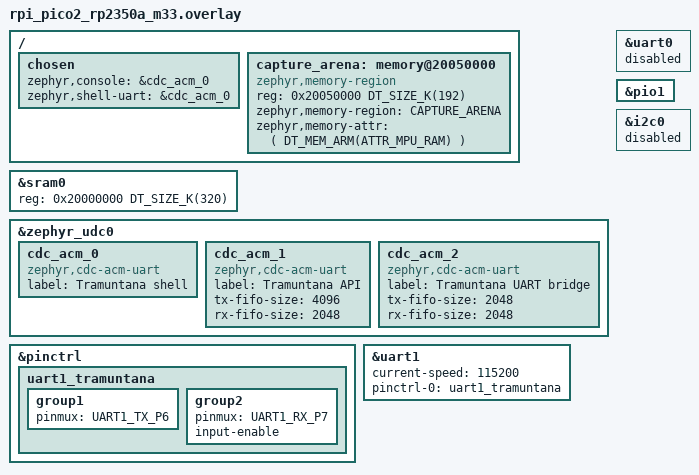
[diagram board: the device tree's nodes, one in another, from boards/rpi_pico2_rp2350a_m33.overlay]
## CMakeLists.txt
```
cmake_minimum_required(VERSION 3.20.0)

find_package(Zephyr REQUIRED HINTS $ENV{ZEPHYR_BASE})
project(tramuntana_fw)

target_sources(app PRIVATE
  src/main.c
  src/usb.c
  src/port.c
  src/board.c
  src/display.c
  src/proto.c
  src/spi.c
  src/i2c.c
  src/scope.c
  src/awg.c
  src/pwm.c
  src/logic.c
  src/bridge.c
  src/arena.c
  src/dmaring.c
  src/shell_cmds.c
  src/watch.c
  src/emu.c
  src/seq.c
  src/stamp.c
)

# images_gen.h / font_gen.h, generated by fw/imgs/convert_images.py and
# fw/imgs/font_gen.py.
target_include_directories(app PRIVATE ${CMAKE_CURRENT_SOURCE_DIR}/../../imgs)
```

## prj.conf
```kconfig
# Tramuntana Lite r1a - main firmware: a USB composite device with three
# CDC-ACM ports (shell / binary API / UART bridge) driving the board's
# instruments. See src/main.c for the map.

CONFIG_GPIO=y
CONFIG_REGULATOR=y
CONFIG_DISPLAY=y
CONFIG_SPI=y
CONFIG_ADC=y
CONFIG_PWM=y
CONFIG_DMA=y
CONFIG_SERIAL=y
CONFIG_UART_INTERRUPT_DRIVEN=y
CONFIG_UART_USE_RUNTIME_CONFIGURE=y
CONFIG_UART_LINE_CTRL=y
CONFIG_HWINFO=y
CONFIG_CRC=y

# USB device (new stack), three CDC-ACM instances registered by src/usb.c.
CONFIG_USB_DEVICE_STACK_NEXT=y
CONFIG_USBD_CDC_ACM_CLASS=y
# CDC-ACM class work (rx/tx fifo handling, irq callbacks) on its own
# thread rather than the system workqueue, so USB never competes with
# the display/LED work items and vice versa.
CONFIG_USBD_CDC_ACM_WORKQUEUE=y
CONFIG_USBD_CDC_ACM_STACK_SIZE=2048
# The shell (and its log backend) runs over CDC-ACM, so the class can't
# log itself without recursing: Zephyr would force this anyway.
CONFIG_USBD_CDC_ACM_LOG_LEVEL_OFF=y

# Shell on the first CDC-ACM port (chosen zephyr,shell-uart in the overlay).
CONFIG_SHELL=y
CONFIG_SHELL_BACKEND_SERIAL=y
CONFIG_SHELL_PROMPT_UART="tramuntana:~$ "
CONFIG_SHELL_CMD_BUFF_SIZE=512
CONFIG_SHELL_ARGC_MAX=40
CONFIG_SHELL_STACK_SIZE=4096
CONFIG_LOG=y
CONFIG_LOG_MODE_DEFERRED=y
CONFIG_LOG_BUFFER_SIZE=2048

CONFIG_MAIN_STACK_SIZE=4096
CONFIG_SYSTEM_WORKQUEUE_STACK_SIZE=2048
CONFIG_HEAP_MEM_POOL_SIZE=8192
CONFIG_CBPRINTF_FP_SUPPORT=y
CONFIG_FPU=y

# The instruments drive the ADC, PWM, DMA and PIO blocks straight
# through the Pico SDK (hardware/*.h); the Zephyr drivers above are what
# pull those SDK sources in (PICOSDK_USE_* are selected by them) and
# bring the blocks out of reset at boot.
```

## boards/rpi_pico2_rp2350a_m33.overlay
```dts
/*
 * Tramuntana Lite r1a on a Pico 2 - see fw/boards/tramuntana_lite_r1a-
 * common.dtsi for the hardware itself. This overlay adds what this app
 * needs on top:
 *
 *   - three CDC-ACM ports on the Pico's USB: cdc_acm_0 (shell/console),
 *     cdc_acm_1 (binary API, src/proto.c), cdc_acm_2 (UART bridge to
 *     &uart1 on DIO1/DIO0, src/bridge.c);
 *   - &uart1 enabled on GPIO6/GPIO7 (its pins are handed over to it only
 *     while the bridge is open, see src/board.c), &uart0 disabled;
 *   - a 192KB "capture arena" carved out of the top of SRAM at a fixed,
 *     128KB-aligned address, so the DMA ring buffers (scope, logic
 *     analyzer, sniffers) can use the DMA's address-wrapping mode without
 *     the linker having to pad .bss to reach an aligned address.
 */

#include "../../../boards/tramuntana_lite_r1a-common.dtsi"
#include <zephyr/dt-bindings/memory-attr/memory-attr-arm.h>

/ {
  chosen {
    zephyr,console = &cdc_acm_0;
    zephyr,shell-uart = &cdc_acm_0;
  };

  capture_arena: memory@20050000 {
    compatible = "zephyr,memory-region", "mmio-sram";
    reg = <0x20050000 DT_SIZE_K(192)>;
    zephyr,memory-region = "CAPTURE_ARENA";
    zephyr,memory-attr = <( DT_MEM_ARM(ATTR_MPU_RAM) )>;
  };
};

/* 520KB total; the arena above takes the top 192KB, the 8KB of scratch
 * banks past 0x20080000 are left alone. */
&sram0 {
  reg = <0x20000000 DT_SIZE_K(320)>;
};

&zephyr_udc0 {
  cdc_acm_0: cdc_acm_0 {
    compatible = "zephyr,cdc-acm-uart";
    label = "Tramuntana shell";
  };
  cdc_acm_1: cdc_acm_1 {
    compatible = "zephyr,cdc-acm-uart";
    label = "Tramuntana API";
    tx-fifo-size = <4096>;
    rx-fifo-size = <2048>;
  };
  cdc_acm_2: cdc_acm_2 {
    compatible = "zephyr,cdc-acm-uart";
    label = "Tramuntana UART bridge";
    tx-fifo-size = <2048>;
    rx-fifo-size = <2048>;
  };
};

/* UART1 = GPIO6 (TX, DIO1) / GPIO7 (RX, DIO0). On the RP2350 these are
 * UART1's CTS/RTS pins, which carry TX/RX through the UART_AUX function
 * (F11), so the bridge gets pins of its own instead of sharing DIO6/DIO7
 * with I2C. src/board.c re-muxes them as the bridge opens and closes. */
&pinctrl {
  uart1_tramuntana: uart1_tramuntana {
    group1 {
      pinmux = <UART1_TX_P6>;
    };

    group2 {
      pinmux = <UART1_RX_P7>;
      input-enable;
    };
  };
};

&uart1 {
  status = "okay";
  current-speed = <115200>;
  pinctrl-0 = <&uart1_tramuntana>;
  pinctrl-names = "default";
};

/* The stock console UART (GPIO0/GPIO1 = DIO7/DIO6) is not used: the
 * console is cdc_acm_0 and those pins belong to I2C. */
&uart0 {
  status = "disabled";
};

/* PIO1 hosts the emulated I2C/SPI targets (src/emu.c); PIO0 is the
 * sniffers' and the logic analyzer's. */
&pio1 {
  status = "okay";
};

/* The hardware I2C0 block is not used (the I2C master is bit-banged so
 * arbitrary START/STOP sequences can be scripted, see src/i2c.c). */
&i2c0 {
  status = "disabled";
};
```

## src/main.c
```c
/*
 * Tramuntana Lite r1a - main firmware.
 *
 * A bench tool for poking at embedded systems: SPI and I2C master and
 * sniffer, oscilloscope, waveform generator, 8-channel logic analyzer
 * and a USB-UART bridge, all on the RP2350 of a Pico 2 running Zephyr.
 *
 * Structure (src/):
 *
 *   usb.c       USB composite device: three CDC-ACM ports
 *   port.c      irq-driven ring-buffered serial port helper
 *   proto.c/h   binary API on the second port (the protocol reference)
 *   shell_cmds.c  human shell on the first port
 *   bridge.c    USB <-> UART1 bridge on the third port
 *   board.c     LED, target power, pull-ups, DIO GPIO, pin arbiter
 *   display.c   ST7735R dashboard
 *   arena.c     capture memory (DMA ring buffers)
 *   spi.c  i2c.c  scope.c  awg.c  logic.c  pwm.c   the instruments
 *   emu.c       the board as an I2C/SPI target (register file on PIO1)
 *   seq.c       sequencer: host-uploaded steps run with us timing
 *   watch.c     timestamped DIO edges for the host's timeline
 *
 * Host side: host/python (library + CLI) and host/webapp (Web Serial).
 */

#include <zephyr/kernel.h>
#include <zephyr/logging/log.h>

#include "usb.h"
#include "board.h"
#include "display.h"
#include "proto.h"
#include "spi.h"
#include "i2c.h"
#include "scope.h"
#include "awg.h"
#include "logic.h"
#include "bridge.h"
#include "watch.h"
#include "emu.h"
#include "seq.h"
#include "stamp.h"
#include "version.h"

LOG_MODULE_REGISTER(main, LOG_LEVEL_INF);

#define SPLASH_MS 1500

int main(void)
{
  usb_init();
  board_init();
  display_init();
  stamp_init();

  spi_drv_init();
  i2c_drv_init();
  scope_init();
  awg_init();
  logic_init();
  bridge_init();
  watch_init();
  emu_init();
  seq_init();
  proto_init();

  ui_set(UI_ROW_SYS, "PWR off PU off");
  ui_set(UI_ROW_NOTE, "fw %s", FW_VERSION);
  led_flash(LED_WHITE, 300);

  printk("Tramuntana Lite r1a fw %s - type 'help'\n", FW_VERSION);

  k_sleep(K_MSEC(SPLASH_MS));
  ui_show();
  return 0;
}
```

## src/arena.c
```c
/*
 * Tramuntana - arena. See arena.h.
 */

#include <zephyr/kernel.h>
#include <zephyr/linker/devicetree_regions.h>
#include <zephyr/devicetree.h>
#include <string.h>

#include "arena.h"

#define ARENA_NODE DT_NODELABEL(capture_arena)

static uint8_t arena_mem[ARENA_SCOPE_BYTES + ARENA_SCOPE_BYTES + ARENA_RING_BYTES]
  Z_GENERIC_SECTION(LINKER_DT_NODE_REGION_NAME(ARENA_NODE));

BUILD_ASSERT(DT_REG_ADDR(ARENA_NODE) % ARENA_SCOPE_BYTES == 0,
             "scope ring must be 32KB aligned");
BUILD_ASSERT((DT_REG_ADDR(ARENA_NODE) + 2 * ARENA_SCOPE_BYTES) % ARENA_RING_BYTES == 0,
             "shared ring must be 128KB aligned");
BUILD_ASSERT(DT_REG_SIZE(ARENA_NODE) >= sizeof(arena_mem), "capture arena too small");

static const char *ring_holder;
static arena_evict_cb_t ring_evict;
static struct k_spinlock ring_lock;

uint8_t *arena_scope(void)
{
  /* First 32KB: aligned to 32KB because the region itself is. */
  return arena_mem;
}

uint8_t *arena_ring(void)
{
  /* Skip 64KB so the ring lands on the 128KB boundary at +0x10000. */
  return arena_mem + 2 * ARENA_SCOPE_BYTES;
}

int arena_ring_claim(const char *who)
{
  k_spinlock_key_t key = k_spin_lock(&ring_lock);

  if (ring_holder != NULL && ring_holder != who) {
    arena_evict_cb_t cb = ring_evict;

    if (cb == NULL) {
      k_spin_unlock(&ring_lock, key);
      return -EBUSY;
    }
    ring_evict = NULL;
    ring_holder = NULL;
    k_spin_unlock(&ring_lock, key);
    cb();
    key = k_spin_lock(&ring_lock);
  }
  ring_holder = who;
  ring_evict = NULL;
  k_spin_unlock(&ring_lock, key);
  return 0;
}

void arena_ring_set_evictable(const char *who, arena_evict_cb_t cb)
{
  k_spinlock_key_t key = k_spin_lock(&ring_lock);

  if (ring_holder == who) {
    ring_evict = cb;
  }
  k_spin_unlock(&ring_lock, key);
}

void arena_ring_release(const char *who)
{
  k_spinlock_key_t key = k_spin_lock(&ring_lock);

  if (ring_holder == who) {
    ring_holder = NULL;
    ring_evict = NULL;
  }
  k_spin_unlock(&ring_lock, key);
}

const char *arena_ring_holder(void)
{
  return ring_holder;
}
```

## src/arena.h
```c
/*
 * Tramuntana - arena: the 192KB capture region reserved at 0x20050000 by
 * the devicetree overlay (boards/rpi_pico2_rp2350a_m33.overlay). Split in two:
 *
 *   0x20050000  32KB   scope ring (ADC samples, DMA address-wrapped)
 *   0x20060000  128KB  shared ring for the logic analyzer and the SPI/I2C
 *                      sniffers - one of them at a time, hence the claim.
 *
 * Both starts are aligned to their own size, which is what the RP2350
 * DMA's ring mode (channel_config_set_ring()) needs.
 */
#pragma once

#include <stdint.h>
#include <stdbool.h>

#define ARENA_SCOPE_BITS  15
#define ARENA_SCOPE_BYTES (1u << ARENA_SCOPE_BITS)
#define ARENA_RING_BITS   17
#define ARENA_RING_BYTES  (1u << ARENA_RING_BITS)

uint8_t *arena_scope(void);
uint8_t *arena_ring(void);

/* The shared ring: -EBUSY if another instrument holds it - unless that
 * holder registered itself as evictable (the logic analyzer keeps a
 * finished capture in the ring for the host to read, but gives it up
 * the moment someone else needs the memory: its evict callback runs
 * first, then the claim succeeds). */
typedef void (*arena_evict_cb_t)(void);
int arena_ring_claim(const char *who);
void arena_ring_release(const char *who);
void arena_ring_set_evictable(const char *who, arena_evict_cb_t cb);
const char *arena_ring_holder(void);
```

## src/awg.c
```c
/*
 * Tramuntana - awg. See awg.h.
 *
 * AOUT0 (J1.7) is GPIO8 behind R3 (2k7) and C3 (1nF): a first-order RC
 * low-pass with its corner at 59kHz. There's no DAC - the "analog"
 * output is the average of a PWM on GPIO8 (slice 4, channel A), so the
 * PWM runs well above that corner. TOP = 255 (8 bits, 586kHz at
 * 150MHz) is the sweet spot for this filter; awg_plan() stretches TOP a
 * little (up to 511) when that lands closer to the requested frequency.
 *
 * One period of the waveform is pre-computed into awg_table[] as PWM
 * compare values and a DMA channel feeds it into the slice's CC register
 * paced by the slice's wrap DREQ - one sample per PWM period. A second,
 * one-word DMA channel restarts the first when the table's done (the
 * pico-sdk "control channel" idiom), so the output keeps going with no
 * CPU involvement until awg_off().
 *
 * Frequency planning: period = clk_sys / f cycles, split between the
 * PWM clock divider (integer, only > 1 at low frequencies), the table
 * length N (as many samples per period as the PWM rate allows, up to
 * AWG_TABLE_MAX) and TOP+1, nudged so the product hits the requested
 * frequency as closely as possible (usually within 0.1%).
 *
 * ARB: the host uploads up to AWG_ARB_MAX 8-bit samples (0..255 =
 * 0..3.3V) with awg_arb_load(); awg_set(AWG_ARB, f, ...) then plays the
 * whole table f times a second, resampled to whatever N the planner
 * picks, scaled by amp/offset (amp = 1650mV, off = 1650mV reproduces
 * the table full-scale).
 */

#include <zephyr/kernel.h>
#include <zephyr/logging/log.h>
#include <hardware/pwm.h>
#include <hardware/dma.h>
#include <math.h>
#include <string.h>

#include "awg.h"
#include "board.h"
#include "display.h"

LOG_MODULE_REGISTER(awg, LOG_LEVEL_INF);

#define AWG_GPIO          GPIO_AOUT0
#define AWG_PWM_MIN_TOP   255
#define AWG_PWM_MAX_TOP   511
#define AWG_TABLE_MAX     4096
#define AWG_MAX_DIV       255
#define AWG_TWO_PI        6.28318530718f

static uint32_t awg_table[AWG_TABLE_MAX];
static const uint32_t *const awg_table_start = awg_table;
static uint8_t arb[AWG_ARB_MAX];
static uint16_t arb_len;

static struct {
  bool running;
  int dma_data;
  int dma_ctrl;
  enum awg_shape shape;
  uint32_t freq_mhz;
  int32_t amp_mv, off_mv;
  uint32_t param;
  uint32_t n, top, div, pwm_hz;
  struct k_mutex lock;
} awg = { .dma_data = -1, .dma_ctrl = -1, .shape = AWG_OFF };

static const char *const shape_names[] = {
  [AWG_SINE] = "SINE", [AWG_TRI] = "TRI", [AWG_SAW] = "SAW", [AWG_SQUARE] = "SQUARE",
  [AWG_STAIRS] = "STAIRS", [AWG_ARB] = "ARB", [AWG_DC] = "DC", [AWG_STEP] = "STEP",
  [AWG_OFF] = "OFF",
};

const char *awg_shape_name(enum awg_shape s)
{
  return (s <= AWG_OFF) ? shape_names[s] : "?";
}

static void awg_ui(void)
{
  uint32_t mhz = awg.freq_mhz;

  if (awg.shape == AWG_OFF) {
    ui_set(UI_ROW_AWG, "off");
  } else if (awg.shape == AWG_DC || awg.shape == AWG_STEP) {
    ui_set(UI_ROW_AWG, "%s %d.%02dV", shape_names[awg.shape], awg.off_mv / 1000,
           (awg.off_mv % 1000) / 10);
  } else if (mhz >= 1000000) {
    ui_set(UI_ROW_AWG, "%s %u.%03ukHz %d.%02dVp", shape_names[awg.shape], mhz / 1000000,
           (mhz / 1000) % 1000, awg.amp_mv / 1000, (awg.amp_mv % 1000) / 10);
  } else {
    ui_set(UI_ROW_AWG, "%s %u.%uHz %d.%02dVp", shape_names[awg.shape], mhz / 1000,
           (mhz / 100) % 10, awg.amp_mv / 1000, (awg.amp_mv % 1000) / 10);
  }
}

static uint32_t mv_to_level(int32_t mv)
{
  mv = CLAMP(mv, 0, AWG_VREF_MV);
  return ((uint32_t)mv * awg.top + AWG_VREF_MV / 2) / AWG_VREF_MV;
}

static void awg_plan(uint32_t clk_hz, uint32_t freq_hz)
{
  double cycles = (double)clk_hz / (double)freq_hz;
  uint32_t div = 1;
  double per;
  uint32_t n, top1 = 0;
  double best_err = -1.0;
  uint32_t cand;

  while (cycles / div > (double)AWG_TABLE_MAX * (AWG_PWM_MAX_TOP + 1) && div < AWG_MAX_DIV) {
    div++;
  }
  per = cycles / div;
  n = (uint32_t)(per / (AWG_PWM_MIN_TOP + 1));
  n = CLAMP(n, 2, AWG_TABLE_MAX);
  for (cand = (n > 4) ? n - 3 : 2; cand <= n + 3 && cand <= AWG_TABLE_MAX; cand++) {
    uint32_t t1 = (uint32_t)(per / cand + 0.5);
    double err;

    t1 = CLAMP(t1, AWG_PWM_MIN_TOP + 1, AWG_PWM_MAX_TOP + 1);
    err = fabs((double)cand * t1 - per);
    if (best_err < 0.0 || err < best_err) {
      best_err = err;
      n = cand;
      top1 = t1;
    }
  }
  awg.div = div;
  awg.n = n;
  awg.top = top1 - 1;
  awg.pwm_hz = clk_hz / (div * top1);
  awg.freq_mhz = (uint32_t)(((uint64_t)clk_hz * 1000ULL) / ((uint64_t)div * n * top1));
}

static void awg_fill_table(void)
{
  uint32_t i;

  for (i = 0; i < awg.n; i++) {
    float phase = (float)i / (float)awg.n;
    float unit;

    switch (awg.shape) {
    case AWG_SINE:
      unit = sinf(AWG_TWO_PI * phase);
      break;
    case AWG_TRI:
      unit = (phase < 0.5f) ? (4.0f * phase - 1.0f) : (3.0f - 4.0f * phase);
      break;
    case AWG_SAW:
      unit = 2.0f * phase - 1.0f;
      break;
    case AWG_SQUARE:
      unit = (phase * 100.0f < (float)awg.param) ? 1.0f : -1.0f;
      break;
    case AWG_STAIRS: {
      uint32_t k = (uint32_t)(phase * (float)awg.param);

      unit = -1.0f + 2.0f * (float)k / (float)(awg.param - 1);
      break;
    }
    case AWG_ARB: {
      /* Nearest-sample resampling of the uploaded table. */
      uint32_t k = (uint32_t)(phase * (float)arb_len);

      if (k >= arb_len) {
        k = arb_len - 1;
      }
      unit = ((float)arb[k] - 127.5f) / 127.5f;
      break;
    }
    default:
      unit = 0.0f;
      break;
    }
    awg_table[i] = mv_to_level(awg.off_mv + (int32_t)((float)awg.amp_mv * unit));
  }
}

static void awg_stop_dma(uint32_t level)
{
  uint slice = pwm_gpio_to_slice_num(AWG_GPIO);

  if (awg.dma_data >= 0) {
    dma_hw->abort = BIT(awg.dma_data) | BIT(awg.dma_ctrl);
    while (dma_hw->abort) {
      /* wait */
    }
    dma_channel_cleanup(awg.dma_data);
    dma_channel_cleanup(awg.dma_ctrl);
    dma_channel_unclaim(awg.dma_data);
    dma_channel_unclaim(awg.dma_ctrl);
    awg.dma_data = awg.dma_ctrl = -1;
  }
  awg.running = false;
  pwm_set_chan_level(slice, PWM_CHAN_A, (uint16_t)level);
}

static void awg_pwm_setup(void)
{
  uint slice = pwm_gpio_to_slice_num(AWG_GPIO);

  pwm_set_clkdiv_int_frac(slice, (uint8_t)awg.div, 0);
  pwm_set_wrap(slice, (uint16_t)awg.top);
  pwm_set_enabled(slice, true);
}

static int awg_start_loop(void)
{
  uint slice = pwm_gpio_to_slice_num(AWG_GPIO);
  dma_channel_config cfg;

  awg.dma_data = dma_claim_unused_channel(false);
  awg.dma_ctrl = dma_claim_unused_channel(false);
  if (awg.dma_data < 0 || awg.dma_ctrl < 0) {
    if (awg.dma_data >= 0) {
      dma_channel_unclaim(awg.dma_data);
    }
    if (awg.dma_ctrl >= 0) {
      dma_channel_unclaim(awg.dma_ctrl);
    }
    awg.dma_data = awg.dma_ctrl = -1;
    return -EBUSY;
  }

  cfg = dma_channel_get_default_config(awg.dma_data);
  channel_config_set_transfer_data_size(&cfg, DMA_SIZE_32);
  channel_config_set_read_increment(&cfg, true);
  channel_config_set_write_increment(&cfg, false);
  channel_config_set_dreq(&cfg, pwm_get_dreq(slice));
  channel_config_set_chain_to(&cfg, awg.dma_ctrl);
  dma_channel_configure(awg.dma_data, &cfg, &pwm_hw->slice[slice].cc, awg_table, awg.n, false);

  cfg = dma_channel_get_default_config(awg.dma_ctrl);
  channel_config_set_transfer_data_size(&cfg, DMA_SIZE_32);
  channel_config_set_read_increment(&cfg, false);
  channel_config_set_write_increment(&cfg, false);
  dma_channel_configure(awg.dma_ctrl, &cfg, &dma_hw->ch[awg.dma_data].al3_read_addr_trig,
                        &awg_table_start, 1, false);

  pwm_set_chan_level(slice, PWM_CHAN_A, (uint16_t)awg_table[0]);
  awg_pwm_setup();
  dma_channel_start(awg.dma_data);
  awg.running = true;
  led_background(LED_MAGENTA);
  return 0;
}

int awg_set(enum awg_shape shape, uint32_t freq_hz, uint16_t amp_mv, uint16_t off_mv,
            uint16_t param, struct awg_status *out)
{
  int ret;

  if (shape > AWG_ARB) {
    return -EINVAL;
  }
  if (freq_hz < AWG_MIN_FREQ_HZ || freq_hz > AWG_MAX_FREQ_HZ) {
    return -EINVAL;
  }
  if (amp_mv > AWG_VREF_MV || off_mv > AWG_VREF_MV) {
    return -EINVAL;
  }
  if (shape == AWG_SQUARE) {
    param = (param == 0 || param > 100) ? 50 : param;
  } else if (shape == AWG_STAIRS) {
    param = (param < 2) ? 8 : MIN(param, 256);
  } else if (shape == AWG_ARB && arb_len == 0) {
    return -EINVAL;
  }

  k_mutex_lock(&awg.lock, K_FOREVER);
  awg_stop_dma(0);
  awg.shape = shape;
  awg.amp_mv = amp_mv;
  awg.off_mv = off_mv;
  awg.param = param;
  awg_plan(board_sysclk_hz(), freq_hz);
  awg_fill_table();
  ret = awg_start_loop();
  if (ret != 0) {
    awg.shape = AWG_OFF;
  }
  k_mutex_unlock(&awg.lock);
  awg_ui();
  if (out != NULL) {
    awg_get_status(out);
  }
  return ret;
}

int awg_dc(uint16_t mv)
{
  if (mv > AWG_VREF_MV) {
    return -EINVAL;
  }
  k_mutex_lock(&awg.lock, K_FOREVER);
  awg.shape = AWG_DC;
  awg.off_mv = mv;
  awg.amp_mv = 0;
  awg.freq_mhz = 0;
  awg.div = 1;
  awg.top = AWG_PWM_MIN_TOP;
  awg_stop_dma(0);
  awg_pwm_setup();
  pwm_set_chan_level(pwm_gpio_to_slice_num(AWG_GPIO), PWM_CHAN_A, (uint16_t)mv_to_level(mv));
  led_background(LED_MAGENTA);
  k_mutex_unlock(&awg.lock);
  awg_ui();
  return 0;
}

int awg_step(uint16_t from_mv, uint16_t to_mv, uint16_t delay_ms)
{
  int ret = awg_dc(from_mv);

  if (ret != 0) {
    return ret;
  }
  k_sleep(K_MSEC(delay_ms));
  ret = awg_dc(to_mv);
  awg.shape = AWG_STEP;
  awg_ui();
  return ret;
}

void awg_off(void)
{
  k_mutex_lock(&awg.lock, K_FOREVER);
  awg_stop_dma(0);
  awg.shape = AWG_OFF;
  awg.freq_mhz = 0;
  led_background(LED_OFF);
  k_mutex_unlock(&awg.lock);
  awg_ui();
}

int awg_arb_load(uint16_t offset, const uint8_t *samples, size_t n)
{
  if (n == 0 || (size_t)offset + n > AWG_ARB_MAX) {
    return -EINVAL;
  }
  k_mutex_lock(&awg.lock, K_FOREVER);
  memcpy(&arb[offset], samples, n);
  /* Loading from 0 restarts the table; appending extends it. */
  arb_len = (offset == 0) ? (uint16_t)n : (uint16_t)MAX(arb_len, offset + n);
  k_mutex_unlock(&awg.lock);
  return 0;
}

uint16_t awg_arb_len(void)
{
  return arb_len;
}

void awg_get_status(struct awg_status *out)
{
  out->running = awg.running || awg.shape == AWG_DC || awg.shape == AWG_STEP;
  out->shape = awg.shape;
  out->freq_mhz = awg.freq_mhz;
  out->amp_mv = (uint16_t)awg.amp_mv;
  out->off_mv = (uint16_t)awg.off_mv;
  out->n = (uint16_t)awg.n;
  out->top = (uint16_t)awg.top;
}

void awg_init(void)
{
  k_mutex_init(&awg.lock);
  awg.shape = AWG_OFF;
  awg.top = AWG_PWM_MIN_TOP;
  awg.div = 1;
  awg_ui();
}
```

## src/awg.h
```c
/*
 * Tramuntana - awg: waveform generator on AOUT0 (PWM 4A through the
 * board's 2k7/1nF RC filter), fed by DMA so it runs in the background.
 * See awg.c.
 */
#pragma once

#include <stdint.h>
#include <stdbool.h>
#include <stddef.h>

enum awg_shape {
  AWG_SINE = 0, AWG_TRI = 1, AWG_SAW = 2, AWG_SQUARE = 3, AWG_STAIRS = 4, AWG_ARB = 5,
  AWG_DC = 6, AWG_STEP = 7, AWG_OFF = 8,
};

#define AWG_MIN_FREQ_HZ  1
#define AWG_MAX_FREQ_HZ  100000
#define AWG_ARB_MAX      4096
#define AWG_VREF_MV      3300

struct awg_status {
  bool running;
  enum awg_shape shape;
  uint32_t freq_mhz;   /* achieved, millihertz */
  uint16_t amp_mv;
  uint16_t off_mv;
  uint16_t n;          /* table length */
  uint16_t top;        /* PWM wrap */
};

void awg_init(void);
/* Periodic shapes (SINE..ARB). 'param': duty % for SQUARE, steps for
 * STAIRS, ignored otherwise. For ARB the table loaded with awg_arb_load()
 * is played back at 'freq' periods per second. */
int awg_set(enum awg_shape shape, uint32_t freq_hz, uint16_t amp_mv, uint16_t off_mv,
            uint16_t param, struct awg_status *out);
int awg_dc(uint16_t mv);
int awg_step(uint16_t from_mv, uint16_t to_mv, uint16_t delay_ms);
void awg_off(void);
int awg_arb_load(uint16_t offset, const uint8_t *samples, size_t n);
uint16_t awg_arb_len(void);
void awg_get_status(struct awg_status *out);
const char *awg_shape_name(enum awg_shape s);
```

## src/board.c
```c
/*
 * Tramuntana - board. See board.h.
 *
 * The DIO header pins are driven straight through the Pico SDK's
 * hardware/gpio.h (SIO registers) rather than Zephyr's GPIO API: the
 * bit-banged I2C master and the pin arbiter both need to change a pad's
 * function and direction in a handful of cycles, and the Zephyr driver
 * is just a wrapper over the same registers anyway. LEDs, the power
 * switch and the pull-up enable are ordinary Zephyr devicetree GPIOs.
 */

#include <zephyr/kernel.h>
#include <zephyr/device.h>
#include <zephyr/drivers/gpio.h>
#include <zephyr/drivers/regulator.h>
#include <zephyr/drivers/hwinfo.h>
#include <zephyr/drivers/clock_control.h>
#include <zephyr/logging/log.h>
#include <cmsis_core.h>
#include <hardware/gpio.h>
#include <hardware/adc.h>
#include <string.h>

#include "board.h"

LOG_MODULE_REGISTER(board, LOG_LEVEL_INF);

const char *const pin_owner_names[OWNER_COUNT] = {
  [OWNER_GPIO] = "gpio", [OWNER_SPI] = "spi", [OWNER_I2C] = "i2c",
  [OWNER_UART] = "uart", [OWNER_PIO] = "pio", [OWNER_PWM] = "pwm",
  [OWNER_EMU] = "emu",
};

static const struct gpio_dt_spec led_r = GPIO_DT_SPEC_GET(DT_ALIAS(led_r), gpios);
static const struct gpio_dt_spec led_g = GPIO_DT_SPEC_GET(DT_ALIAS(led_g), gpios);
static const struct gpio_dt_spec led_b = GPIO_DT_SPEC_GET(DT_ALIAS(led_b), gpios);
static const struct gpio_dt_spec pu_en =
  GPIO_DT_SPEC_GET_BY_IDX(DT_PATH(zephyr_user), dio_pu_enable_gpios, 0);
static const struct device *const target_reg = DEVICE_DT_GET(DT_ALIAS(targetpwr));

static struct {
  enum pin_owner owner[DIO_COUNT];
  bool exclusive[DIO_COUNT];
  bool pullups;
  uint32_t pullups_changes;
  enum led_color led_bg;
  void (*on_change)(void);
  struct k_work_delayable led_work;
  struct k_spinlock lock;
} board;

/* --- LED --------------------------------------------------------------- */

/* Straight to the SIO registers (the LEDs are active low): led_set() sits
 * in the path of every bus transaction, and three gpio_pin_set_dt()
 * calls cost ~20us where one masked write costs nothing. */
static void led_apply(enum led_color c)
{
  uint32_t mask = BIT(led_r.pin) | BIT(led_g.pin) | BIT(led_b.pin);
  uint32_t on = 0;

  if (c == LED_RED || c == LED_YELLOW || c == LED_MAGENTA || c == LED_WHITE) {
    on |= BIT(led_r.pin);
  }
  if (c == LED_GREEN || c == LED_YELLOW || c == LED_CYAN || c == LED_WHITE) {
    on |= BIT(led_g.pin);
  }
  if (c == LED_BLUE || c == LED_CYAN || c == LED_MAGENTA || c == LED_WHITE) {
    on |= BIT(led_b.pin);
  }
  gpio_put_masked(mask, mask & ~on);
}

static void led_work_fn(struct k_work *work)
{
  ARG_UNUSED(work);
  led_apply(board.led_bg);
}

void led_set(enum led_color color)
{
  if (k_work_delayable_is_pending(&board.led_work)) {
    k_work_cancel_delayable(&board.led_work);
  }
  led_apply(color);
}

void led_background(enum led_color color)
{
  board.led_bg = color;
  if (!k_work_delayable_is_pending(&board.led_work)) {
    led_apply(color);
  }
}

void led_idle(void)
{
  led_set(board.led_bg);
}

void led_flash(enum led_color color, int ms)
{
  led_apply(color);
  k_work_reschedule(&board.led_work, K_MSEC(ms));
}

/* --- power / pull-ups -------------------------------------------------- */

/* The regulator API is reference counted: every enable needs its own
 * disable. 'power on' twice and 'power off' once would leave the rail on,
 * so only a real change of state reaches the regulator. */
void board_on_change(void (*fn)(void))
{
  board.on_change = fn;
}

static void board_changed(void)
{
  if (board.on_change != NULL) {
    board.on_change();
  }
}

void board_power_set(bool on)
{
  if (on == regulator_is_enabled(target_reg)) {
    return;
  }
  if (on) {
    (void)regulator_enable(target_reg);
  } else {
    (void)regulator_disable(target_reg);
  }
  board_changed();
}

bool board_power_get(void)
{
  return regulator_is_enabled(target_reg);
}

/* R12/R13 (4k7) hang from GPIO10 on the connector side of DIO6/DIO7.
 * On = GPIO10 driven high. Off = GPIO10 disconnected (output driver off,
 * input isolated), never driven low: that would turn the two 4k7 into
 * pull-downs on the target's I2C bus. GPIO_DISCONNECTED is 0 and the
 * RP2xxx driver tests flags == GPIO_DISCONNECTED, so it goes through
 * gpio_pin_configure() without the devicetree flags. */
static void pullups_apply(bool on)
{
  if (on) {
    gpio_pin_configure_dt(&pu_en, GPIO_OUTPUT_ACTIVE);
  } else {
    gpio_pin_configure(pu_en.port, pu_en.pin, GPIO_DISCONNECTED);
  }
}

void board_pullups_set(bool on)
{
  pullups_apply(on);
  board.pullups = on;
  board.pullups_changes++;
  board_changed();
}

uint32_t board_pullups_changes(void)
{
  return board.pullups_changes;
}

bool board_pullups_get(void)
{
  return board.pullups;
}

/* --- pin arbiter -------------------------------------------------------- */

static void pin_apply_owner(int dio, enum pin_owner who)
{
  uint gpio = DIO_GPIO(dio);

  switch (who) {
  case OWNER_SPI:
    if (gpio == GPIO_SPI_CS) {
      /* CS is a GPIO the SPI driver toggles by hand (see spi.c): idle high,
       * level and direction set before the function switch so the pin
       * never glitches low on the way (a target would see a select). */
      gpio_put(gpio, 1);
      gpio_set_dir(gpio, GPIO_OUT);
      gpio_set_function(gpio, GPIO_FUNC_SIO);
    } else {
      gpio_set_function(gpio, GPIO_FUNC_SPI);
    }
    break;
  case OWNER_UART:
    /* GPIO6/7 are UART1's CTS/RTS; TX/RX reach them through UART_AUX. */
    gpio_set_function(gpio, GPIO_FUNC_UART_AUX);
    break;
  case OWNER_PIO:
    gpio_set_function(gpio, GPIO_FUNC_PIO0);
    break;
  case OWNER_PWM:
    gpio_set_function(gpio, GPIO_FUNC_PWM);
    break;
  case OWNER_EMU:
    /* Released (input) in PIO1's latch before emu.c sets directions. */
    gpio_set_function(gpio, GPIO_FUNC_PIO1);
    break;
  case OWNER_GPIO:
  case OWNER_I2C:
  default:
    /* Plain SIO input, no internal pulls: the target's own levels rule.
     * The bit-banged I2C drives the pad low by flipping it to output.
     * Direction first, then the function switch, so the pad never sees
     * SIO's (low) output value on the way to becoming an input. */
    gpio_set_dir(gpio, GPIO_IN);
    gpio_put(gpio, 0);
    gpio_set_function(gpio, GPIO_FUNC_SIO);
    break;
  }
  gpio_set_pulls(gpio, false, false);
  gpio_set_input_enabled(gpio, true);
}

int board_pins_claim(uint8_t dio_mask, enum pin_owner who, bool exclusive)
{
  k_spinlock_key_t key = k_spin_lock(&board.lock);
  int i;

  for (i = 0; i < DIO_COUNT; i++) {
    if ((dio_mask & BIT(i)) && board.exclusive[i] && board.owner[i] != who) {
      k_spin_unlock(&board.lock, key);
      LOG_DBG("DIO%d is held by %s", i, pin_owner_names[board.owner[i]]);
      return -EBUSY;
    }
  }
  for (i = 0; i < DIO_COUNT; i++) {
    if (dio_mask & BIT(i)) {
      if (board.owner[i] != who) {
        pin_apply_owner(i, who);
      }
      board.owner[i] = who;
      board.exclusive[i] = exclusive;
    }
  }
  k_spin_unlock(&board.lock, key);
  return 0;
}

void board_pins_release(uint8_t dio_mask, enum pin_owner who)
{
  k_spinlock_key_t key = k_spin_lock(&board.lock);
  int i;

  for (i = 0; i < DIO_COUNT; i++) {
    if ((dio_mask & BIT(i)) && board.owner[i] == who) {
      board.owner[i] = OWNER_GPIO;
      board.exclusive[i] = false;
      pin_apply_owner(i, OWNER_GPIO);
    }
  }
  k_spin_unlock(&board.lock, key);
}

enum pin_owner board_pin_owner(int dio)
{
  return board.owner[dio];
}

bool board_pin_exclusive(int dio)
{
  return board.exclusive[dio];
}

uint32_t board_pins_snapshot(void)
{
  uint32_t v = 0;
  int i;

  for (i = 0; i < DIO_COUNT; i++) {
    v |= ((uint32_t)(board.owner[i] & 0x7) | (board.exclusive[i] ? 0x8 : 0)) << (4 * i);
  }
  return v;
}

/* --- DIO as GPIO --------------------------------------------------------- */

int board_dio_dir(uint8_t mask, uint8_t out_mask)
{
  int ret = board_pins_claim(mask, OWNER_GPIO, false);
  int i;

  if (ret != 0) {
    return ret;
  }
  for (i = 0; i < DIO_COUNT; i++) {
    if (mask & BIT(i)) {
      gpio_set_dir(DIO_GPIO(i), (out_mask & BIT(i)) ? GPIO_OUT : GPIO_IN);
    }
  }
  return 0;
}

int board_dio_write(uint8_t mask, uint8_t value)
{
  int i;

  for (i = 0; i < DIO_COUNT; i++) {
    if (mask & BIT(i)) {
      if (board.owner[i] != OWNER_GPIO) {
        return -EPERM;
      }
      gpio_put(DIO_GPIO(i), (value >> i) & 1);
    }
  }
  return 0;
}

uint8_t board_dio_read(void)
{
  uint32_t all = gpio_get_all();
  uint8_t v = 0;
  int i;

  for (i = 0; i < DIO_COUNT; i++) {
    if (all & BIT(DIO_GPIO(i))) {
      v |= BIT(i);
    }
  }
  return v;
}

/* --- misc ----------------------------------------------------------------- */

K_MUTEX_DEFINE(board_adc_mutex);

int board_adc_read_mv(int channel)
{
  uint16_t raw;

  if (channel < 0 || channel > 1) {
    return -EINVAL;
  }
  if (k_mutex_lock(&board_adc_mutex, K_NO_WAIT) != 0) {
    return -EBUSY;
  }
  adc_select_input((uint)channel);
  raw = pico_adc_read();
  k_mutex_unlock(&board_adc_mutex);
  return (int)(((uint32_t)raw * BOARD_VREF_MV + 2047) / 4095);
}

uint32_t board_sysclk_hz(void)
{
  return CONFIG_SYS_CLOCK_HW_CYCLES_PER_SEC;
}

uint32_t board_time_us(void)
{
  return (uint32_t)k_cyc_to_us_floor64(k_cycle_get_64());
}

uint32_t board_ns_to_cycles(uint32_t ns)
{
  return (uint32_t)(((uint64_t)ns * board_sysclk_hz()) / 1000000000ULL);
}

void board_delay_ns(uint32_t ns)
{
  board_delay_cycles(board_ns_to_cycles(ns));
}

void board_chip_id(uint8_t out[8])
{
  memset(out, 0, 8);
  hwinfo_get_device_id(out, 8);
}

void board_init(void)
{
  int i;

  gpio_pin_configure_dt(&led_r, GPIO_OUTPUT_INACTIVE);
  gpio_pin_configure_dt(&led_g, GPIO_OUTPUT_INACTIVE);
  gpio_pin_configure_dt(&led_b, GPIO_OUTPUT_INACTIVE);
  pullups_apply(false);
  k_work_init_delayable(&board.led_work, led_work_fn);
  board.led_bg = LED_OFF;

  if (!device_is_ready(target_reg)) {
    LOG_ERR("target regulator not ready");
  }

  /* Cycle counter for board_delay_ns(). */
  CoreDebug->DEMCR |= CoreDebug_DEMCR_TRCENA_Msk;
  DWT->CYCCNT = 0;
  DWT->CTRL |= DWT_CTRL_CYCCNTENA_Msk;

  /* Whatever the devicetree pinctrl groups muxed at boot (SPI0 on
   * DIO2..5, UART1 on DIO1/0), start with every header pin as a plain
   * input: instruments claim what they need when they need it. */
  for (i = 0; i < DIO_COUNT; i++) {
    board.owner[i] = OWNER_GPIO;
    board.exclusive[i] = false;
    pin_apply_owner(i, OWNER_GPIO);
  }
}
```

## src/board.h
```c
/*
 * Tramuntana - board: everything that isn't an instrument. The RGB LED,
 * the target's switched 3.3V rail, the I2C pull-up bias, the DIO header
 * as plain GPIO, single-shot ADC readings, a cycle-accurate busy wait,
 * and - the important one - the pin arbiter that decides which function
 * owns each DIO pin at any moment.
 *
 * Header/GPIO map (fw/boards/tramuntana_lite_r1a-common.dtsi):
 *
 *   DIOn = GPIO(7-n)     DIO0/1  = UART1 RX/TX (GPIO7/6, UART_AUX function)
 *                        DIO2..5 = SPI0 CSN/RX/TX/SCK (GPIO5..2)
 *                        DIO6/7  = I2C SCL/SDA (bit-banged)
 *   AIN0/1 = GPIO26/27   AOUT0 = GPIO8 (PWM 4A)
 *   PU_EN = GPIO10       PWR_EN = GPIO11 (active low)
 *   LED R/G/B = GPIO21/20/22 (active low, common anode)
 *
 * Pin arbiter: every instrument that *drives* header pins claims a DIO
 * mask with its owner id. Masters (SPI, I2C), PWM outputs and plain GPIO use are
 * "soft" owners: they keep the pins between operations (so the bus idles
 * at the right levels) but anyone else can take the pins over. The UART
 * bridge claims "exclusive": while it holds pins, any other claim on
 * them fails with -EBUSY, and the pins go back to plain GPIO inputs when
 * released. The claim also sets the pad's function (SIO / SPI / UART / PWM) so
 * callers never touch gpio_set_function() themselves.
 *
 * Passive instruments (sniffers, logic analyzer) don't claim anything:
 * the PIO reads every pad's input whatever its function select, so they
 * can watch a bus while this board's own master, the bridge, or a target
 * drives it.
 */
#pragma once

#include <stdbool.h>
#include <stdint.h>

#define DIO_COUNT     8
#define DIO_MASK_ALL  0xFF
#define DIO_MASK_SPI  (BIT(2) | BIT(3) | BIT(4) | BIT(5))
#define DIO_MASK_I2C  (BIT(6) | BIT(7))
#define DIO_MASK_UART (BIT(0) | BIT(1))

/* DIO index -> RP2350 GPIO number. */
#define DIO_GPIO(n) (7 - (n))

#define GPIO_AIN0    26
#define GPIO_AIN1    27
#define GPIO_AOUT0   8
#define GPIO_PU_EN   10
#define GPIO_PWR_EN  11
#define GPIO_SPI_CS  5  /* DIO2 */
#define GPIO_SPI_SCK 2  /* DIO5 */
#define GPIO_SPI_TX  3  /* DIO4, MOSI */
#define GPIO_SPI_RX  4  /* DIO3, MISO */
#define GPIO_I2C_SCL 1  /* DIO6 */
#define GPIO_I2C_SDA 0  /* DIO7 */
#define GPIO_UART_TX 6  /* DIO1, UART1 TX via UART_AUX */
#define GPIO_UART_RX 7  /* DIO0, UART1 RX via UART_AUX */

#define BOARD_VREF_MV 3300

enum pin_owner {
  OWNER_GPIO = 0,
  OWNER_SPI,
  OWNER_I2C,
  OWNER_UART,
  OWNER_PIO,     /* sniffers, logic analyzer */
  OWNER_PWM,     /* PWM outputs (src/pwm.c) */
  OWNER_EMU,     /* emulated I2C/SPI target on PIO1 (src/emu.c) */
  OWNER_COUNT,
};

extern const char *const pin_owner_names[OWNER_COUNT];

/* Configures LEDs/power/pull-ups (all off), parks every DIO as a plain
 * GPIO input and enables the cycle counter. Call once at boot. */
void board_init(void);

/* --- pin arbiter --- */
int board_pins_claim(uint8_t dio_mask, enum pin_owner who, bool exclusive);
void board_pins_release(uint8_t dio_mask, enum pin_owner who);
enum pin_owner board_pin_owner(int dio);
bool board_pin_exclusive(int dio);
/* Owner id of each DIO packed for status reports: 4 bits per pin,
 * bit 3 = exclusive, bits 2:0 = owner. */
uint32_t board_pins_snapshot(void);

/* --- LED --- */
enum led_color {
  LED_OFF, LED_RED, LED_GREEN, LED_BLUE, LED_YELLOW, LED_CYAN, LED_MAGENTA, LED_WHITE,
};
void led_set(enum led_color color);          /* immediate */
void led_background(enum led_color color);   /* what 'idle' means (e.g. AWG running) */
void led_idle(void);                         /* back to the background colour */
void led_flash(enum led_color color, int ms); /* non-blocking: colour, then idle */

/* --- target power / pull-ups --- */
void board_power_set(bool on);
bool board_power_get(void);
void board_pullups_set(bool on);
bool board_pullups_get(void);
/* Counts every board_pullups_set(). An instrument that sets the pull-ups
 * for its own use (sniffer, emulator) and puts them back when it stops
 * only does so if this hasn't moved since: a change made meanwhile by the
 * user wins. */
uint32_t board_pullups_changes(void);
/* Called (from the caller's thread) after the target power or the pull-ups
 * change, whoever changed them - the dashboard redraws its lines. */
void board_on_change(void (*fn)(void));

/* --- DIO as GPIO (claims the pins as OWNER_GPIO, soft) --- */
int board_dio_dir(uint8_t mask, uint8_t out_mask);
int board_dio_write(uint8_t mask, uint8_t value);
uint8_t board_dio_read(void);

/* --- misc --- */
/* Single-shot reading of AIN0/AIN1 in millivolts, or a negative errno
 * (e.g. -EBUSY while the scope owns the ADC). */
int board_adc_read_mv(int channel);
uint32_t board_sysclk_hz(void);
/* The board clock in microseconds since boot, truncated to 32 bits (wraps
 * after ~71 minutes; hosts unwrap it). Every timestamped event uses it. */
uint32_t board_time_us(void);
/* Busy waits on the Cortex-M33 cycle counter (DWT), good down to a few
 * tens of ns - for the bit-banged I2C. board_delay_ns() does a 64-bit
 * division to convert, so hot loops precompute cycles with
 * board_ns_to_cycles() and use board_delay_cycles(). */
void board_delay_ns(uint32_t ns);
uint32_t board_ns_to_cycles(uint32_t ns);
static inline uint32_t board_cycles(void);
static inline void board_delay_cycles(uint32_t cycles);
/* Unique chip id (from hwinfo), 8 bytes. */
void board_chip_id(uint8_t out[8]);

#include <cmsis_core.h>

static inline uint32_t board_cycles(void)
{
  return DWT->CYCCNT;
}

static inline void board_delay_cycles(uint32_t cycles)
{
  uint32_t start = DWT->CYCCNT;

  while ((uint32_t)(DWT->CYCCNT - start) < cycles) {
    /* spin */
  }
}
```

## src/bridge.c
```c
/*
 * Tramuntana - bridge. See bridge.h.
 *
 * Both ends are 'port' ring buffers (port.h): the third CDC-ACM instance
 * on the USB side and &uart1 (PL011, GPIO6 TX / GPIO7 RX = DIO1 / DIO0,
 * through the RP2350's UART_AUX pin function) on the header side. One thread shuttles bytes both ways and, once per
 * loop, mirrors the host's line coding: whatever baud rate / parity /
 * stop bits the host program set on /dev/ttyACM2 is applied to UART1
 * with uart_configure(), so 'picocom -b 9600 /dev/ttyACM2' just works.
 *
 * In BRIDGE_AUTO (the default) the bridge follows DTR: opening the port
 * on the host claims DIO0/DIO1 for UART1 (exclusively - plain GPIO use of
 * those two pins gets -EBUSY meanwhile), closing it releases them. The
 * bridge has pins of its own, so it runs alongside the SPI and I2C
 * masters.
 */

#include <zephyr/kernel.h>
#include <zephyr/device.h>
#include <zephyr/drivers/uart.h>
#include <zephyr/logging/log.h>
#include <string.h>

#include <hardware/gpio.h>

#include "bridge.h"
#include "port.h"
#include "usb.h"
#include "board.h"
#include "display.h"
#include "proto.h"

LOG_MODULE_REGISTER(bridge, LOG_LEVEL_INF);

static const struct device *const uart_dev = DEVICE_DT_GET(DT_NODELABEL(uart1));

static struct port usb_port;
static struct port hw_port;
static uint8_t usb_rx[2048], usb_tx[2048], hw_rx[2048], hw_tx[2048];

static struct {
  enum bridge_mode mode;
  uint32_t forced_baud;   /* 0 = follow the host */
  uint32_t baud;          /* currently applied */
  struct uart_config applied;
  bool active;
  bool ready;
  /* control lines */
  enum bridge_ctrl_mode ctrl;
  enum bridge_mode mode_before_ctrl;
  uint8_t reset_dio;
  uint8_t boot_dio;
  bool dtr;
  bool rts;
  bool reset_low;
  bool boot_low;
} br;

K_THREAD_STACK_DEFINE(bridge_stack, 2048);
static struct k_thread bridge_thread_data;

static void bridge_ui(void)
{
  if (!br.ready) {
    ui_set(UI_ROW_UART, "n/a");
  } else if (br.active) {
    ui_set(UI_ROW_UART, "%u %u%c%u bridge%s", br.baud, br.applied.data_bits + 5,
           br.applied.parity == UART_CFG_PARITY_NONE ? 'N' :
           br.applied.parity == UART_CFG_PARITY_EVEN ? 'E' : 'O',
           br.applied.stop_bits == UART_CFG_STOP_BITS_2 ? 2 : 1,
           br.ctrl == BRIDGE_CTRL_OFF ? "" : " +ctl");
  } else {
    ui_set(UI_ROW_UART, "%s", br.mode == BRIDGE_OFF ? "off" : "idle (open ACM2)");
  }
}

static void bridge_apply_line_coding(void)
{
  struct uart_config cfg;

  if (uart_config_get(usb_port.dev, &cfg) != 0) {
    cfg.baudrate = 115200;
    cfg.parity = UART_CFG_PARITY_NONE;
    cfg.stop_bits = UART_CFG_STOP_BITS_1;
    cfg.data_bits = UART_CFG_DATA_BITS_8;
  }
  cfg.flow_ctrl = UART_CFG_FLOW_CTRL_NONE;
  if (br.forced_baud != 0) {
    cfg.baudrate = br.forced_baud;
  }
  if (cfg.baudrate == 0) {
    cfg.baudrate = 115200;
  }
  if (memcmp(&cfg, &br.applied, sizeof(cfg)) != 0) {
    if (uart_configure(uart_dev, &cfg) == 0) {
      br.applied = cfg;
      br.baud = cfg.baudrate;
      bridge_ui();
    }
  }
}

static bool bridge_host_open(void)
{
  return br.dtr;
}

/* Open-drain: low = output (the pad's output value stays 0), released =
 * input, so the target's own pull-up sets the high level. */
static void ctrl_pin(uint8_t dio, bool low)
{
  if (dio == BRIDGE_CTRL_NO_PIN) {
    return;
  }
  gpio_set_dir(DIO_GPIO(dio), low ? GPIO_OUT : GPIO_IN);
}

static void ctrl_apply(void)
{
  if (br.ctrl == BRIDGE_CTRL_DIRECT) {
    br.reset_low = br.rts;
    br.boot_low = br.dtr;
  } else if (br.ctrl == BRIDGE_CTRL_ESP) {
    br.reset_low = br.rts && !br.dtr;
    br.boot_low = br.dtr && !br.rts;
  } else {
    br.reset_low = false;
    br.boot_low = false;
    return;
  }
  ctrl_pin(br.reset_dio, br.reset_low);
  ctrl_pin(br.boot_dio, br.boot_low);
}

/* Reads the host's DTR/RTS; on a change drives the control pins and
 * tells the host (EVT_LINE, for the timeline). */
static void bridge_poll_lines(void)
{
  uint32_t dtr = 0, rts = 0;

  uart_line_ctrl_get(usb_port.dev, UART_LINE_CTRL_DTR, &dtr);
  uart_line_ctrl_get(usb_port.dev, UART_LINE_CTRL_RTS, &rts);
  if ((dtr != 0) == br.dtr && (rts != 0) == br.rts) {
    return;
  }
  br.dtr = dtr != 0;
  br.rts = rts != 0;
  ctrl_apply();
  {
    uint8_t evt[6];

    wr32(evt, board_time_us());
    evt[4] = br.dtr;
    evt[5] = br.rts;
    proto_send_event(EVT_LINE, evt, sizeof(evt));
  }
}

static int bridge_activate(void)
{
  int ret = board_pins_claim(DIO_MASK_UART, OWNER_UART, true);

  if (ret != 0) {
    return ret;
  }
  memset(&br.applied, 0, sizeof(br.applied));
  bridge_apply_line_coding();
  port_rx_flush(&hw_port);
  port_rx_flush(&usb_port);
  br.active = true;
  bridge_ui();
  ui_activity("UART on");
  return 0;
}

static void bridge_deactivate(void)
{
  board_pins_release(DIO_MASK_UART, OWNER_UART);
  br.active = false;
  bridge_ui();
}

static void bridge_thread(void *a, void *b, void *c)
{
  uint8_t buf[256];
  int idle_loops = 0;

  ARG_UNUSED(a);
  ARG_UNUSED(b);
  ARG_UNUSED(c);

  for (;;) {
    bool want;

    bridge_poll_lines();
    want = (br.mode == BRIDGE_ON) || (br.mode == BRIDGE_AUTO && bridge_host_open());

    if (want && !br.active) {
      if (bridge_activate() != 0) {
        k_sleep(K_MSEC(200)); /* pins busy: retry later */
        continue;
      }
    } else if (!want && br.active) {
      bridge_deactivate();
    }

    if (!br.active) {
      k_sleep(K_MSEC(50));
      continue;
    }

    if (++idle_loops >= 10) {
      bridge_apply_line_coding();
      idle_loops = 0;
    }

    {
      size_t n = port_read(&usb_port, buf, sizeof(buf), K_NO_WAIT);
      bool moved = false;

      if (n > 0) {
        port_write(&hw_port, buf, n, K_MSEC(100));
        moved = true;
      }
      n = port_read(&hw_port, buf, sizeof(buf), K_NO_WAIT);
      if (n > 0) {
        port_write(&usb_port, buf, n, K_MSEC(20));
        moved = true;
      }
      if (!moved) {
        k_sleep(K_MSEC(1));
      }
    }
  }
}

int bridge_conf(enum bridge_mode mode, uint32_t baud)
{
  if (mode > BRIDGE_OFF) {
    return -EINVAL;
  }
  if (!br.ready) {
    return -ENODEV;
  }
  br.mode = mode;
  br.forced_baud = baud;
  bridge_ui();
  return 0;
}

void bridge_status(bool *active, uint32_t *baud, uint32_t *rx, uint32_t *tx)
{
  *active = br.active;
  *baud = br.baud;
  *rx = hw_port.rx_total;   /* bytes received from the target */
  *tx = hw_port.tx_total;   /* bytes sent to the target */
}

enum bridge_mode bridge_get_mode(void)
{
  return br.mode;
}

static bool ctrl_dio_ok(uint8_t dio)
{
  return dio == BRIDGE_CTRL_NO_PIN || (dio >= 2 && dio < DIO_COUNT);
}

static uint8_t ctrl_mask(uint8_t reset_dio, uint8_t boot_dio)
{
  return (reset_dio != BRIDGE_CTRL_NO_PIN ? BIT(reset_dio) : 0) |
         (boot_dio != BRIDGE_CTRL_NO_PIN ? BIT(boot_dio) : 0);
}

int bridge_ctrl(enum bridge_ctrl_mode mode, uint8_t reset_dio, uint8_t boot_dio)
{
  uint8_t mask;
  int ret, i;

  if (mode > BRIDGE_CTRL_ESP) {
    return -EINVAL;
  }
  if (!br.ready) {
    return -ENODEV;
  }
  if (mode != BRIDGE_CTRL_OFF &&
      (!ctrl_dio_ok(reset_dio) || !ctrl_dio_ok(boot_dio) ||
       (reset_dio == boot_dio && reset_dio != BRIDGE_CTRL_NO_PIN))) {
    return -EINVAL;
  }
  /* Drop the previous pins first (released = plain inputs again). */
  if (br.ctrl != BRIDGE_CTRL_OFF) {
    board_pins_release(ctrl_mask(br.reset_dio, br.boot_dio), OWNER_UART);
    br.mode = br.mode_before_ctrl;
    br.ctrl = BRIDGE_CTRL_OFF;
  }
  if (mode == BRIDGE_CTRL_OFF) {
    br.reset_low = br.boot_low = false;
    bridge_ui();
    return 0;
  }
  mask = ctrl_mask(reset_dio, boot_dio);
  ret = board_pins_claim(mask, OWNER_UART, true);
  if (ret != 0) {
    return ret;
  }
  /* The claim muxed them to UART_AUX like DIO0/1: these two are plain
   * open-drain GPIOs instead. Input first, output value 0 for "low". */
  for (i = 0; i < DIO_COUNT; i++) {
    if (mask & BIT(i)) {
      gpio_set_dir(DIO_GPIO(i), GPIO_IN);
      gpio_put(DIO_GPIO(i), 0);
      gpio_set_function(DIO_GPIO(i), GPIO_FUNC_SIO);
    }
  }
  br.reset_dio = reset_dio;
  br.boot_dio = boot_dio;
  br.mode_before_ctrl = br.mode;
  br.mode = BRIDGE_ON;
  br.ctrl = mode;
  ctrl_apply();
  bridge_ui();
  return 0;
}

int bridge_target_write(const uint8_t *data, size_t n)
{
  if (!br.active) {
    return -EPERM;
  }
  return port_write(&hw_port, data, n, K_MSEC(100)) == n ? 0 : -ETIMEDOUT;
}

void bridge_ctrl_get(struct bridge_ctrl_status *out)
{
  out->mode = br.ctrl;
  out->reset_dio = br.reset_dio;
  out->boot_dio = br.boot_dio;
  out->dtr = br.dtr;
  out->rts = br.rts;
  out->reset_low = br.reset_low;
  out->boot_low = br.boot_low;
}

void bridge_init(void)
{
  if (port_init(&usb_port, USB_ACM_BRIDGE, usb_rx, sizeof(usb_rx), usb_tx, sizeof(usb_tx), true) != 0 ||
      port_init(&hw_port, uart_dev, hw_rx, sizeof(hw_rx), hw_tx, sizeof(hw_tx), false) != 0) {
    LOG_ERR("bridge ports not ready");
    br.ready = false;
    bridge_ui();
    return;
  }
  br.ready = true;
  br.mode = BRIDGE_AUTO;
  /* Above the sequencer (seq.c, priority 2): its busy waits must not hold
   * up the target's bytes, a new baud rate or a DTR/RTS change for the
   * length of a run. The work here is short (a few bytes, then sleep), so
   * it only adds microseconds of jitter to a sequence. */
  k_thread_create(&bridge_thread_data, bridge_stack, K_THREAD_STACK_SIZEOF(bridge_stack),
                  bridge_thread, NULL, NULL, NULL, K_PRIO_PREEMPT(1), 0, K_NO_WAIT);
  k_thread_name_set(&bridge_thread_data, "bridge");
  bridge_ui();
}
```

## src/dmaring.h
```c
/*
 * Tramuntana - dmaring: an endless circular DMA capture into a buffer of
 * any size (power of two not required).
 *
 * The RP2350 DMA's own address-wrapping mode (RING_SIZE) tops out at
 * 32KB, so bigger rings are built the way the datasheet suggests: two
 * data channels, one per half of the buffer, chained to each other
 * through two one-word control channels that rewrite the next data
 * channel's write address (via its WRITE_ADDR_TRIG alias) and so
 * restart it. A -> ctlB -> B -> ctlA -> A -> ... forever, with the
 * peripheral's DREQ pacing whichever data channel is running.
 *
 * Consumers track the write position with dma_ring_write_offset() (bytes
 * from the start of the buffer, wrapping at 'size') and keep their own
 * running total, like scope.c does with its hardware ring.
 */
#pragma once

#include <stdint.h>
#include <stddef.h>
#include <stdbool.h>

struct dma_ring {
  int data[2];
  int ctl[2];
  uint8_t *buf;
  uint32_t size;
  uint32_t half;
  uint32_t item_size;
  uint32_t reload[2];   /* write addresses the control channels feed back */
  bool running;
};

/* Claims four channels and starts streaming 'item_size' (1/2/4) byte
 * items from 'src' (a FIFO register) into buf[0..size), paced by 'dreq'.
 * 'size' must be a multiple of 2 * item_size. Returns 0 or -EBUSY when
 * no channels are free. */
int dma_ring_start(struct dma_ring *r, uint8_t *buf, uint32_t size, uint32_t item_size,
                   uint32_t dreq, const volatile void *src);

/* Where the next item will be written, as a byte offset into buf. */
uint32_t dma_ring_write_offset(const struct dma_ring *r);

/* Aborts everything and releases the channels. */
void dma_ring_stop(struct dma_ring *r);
```
